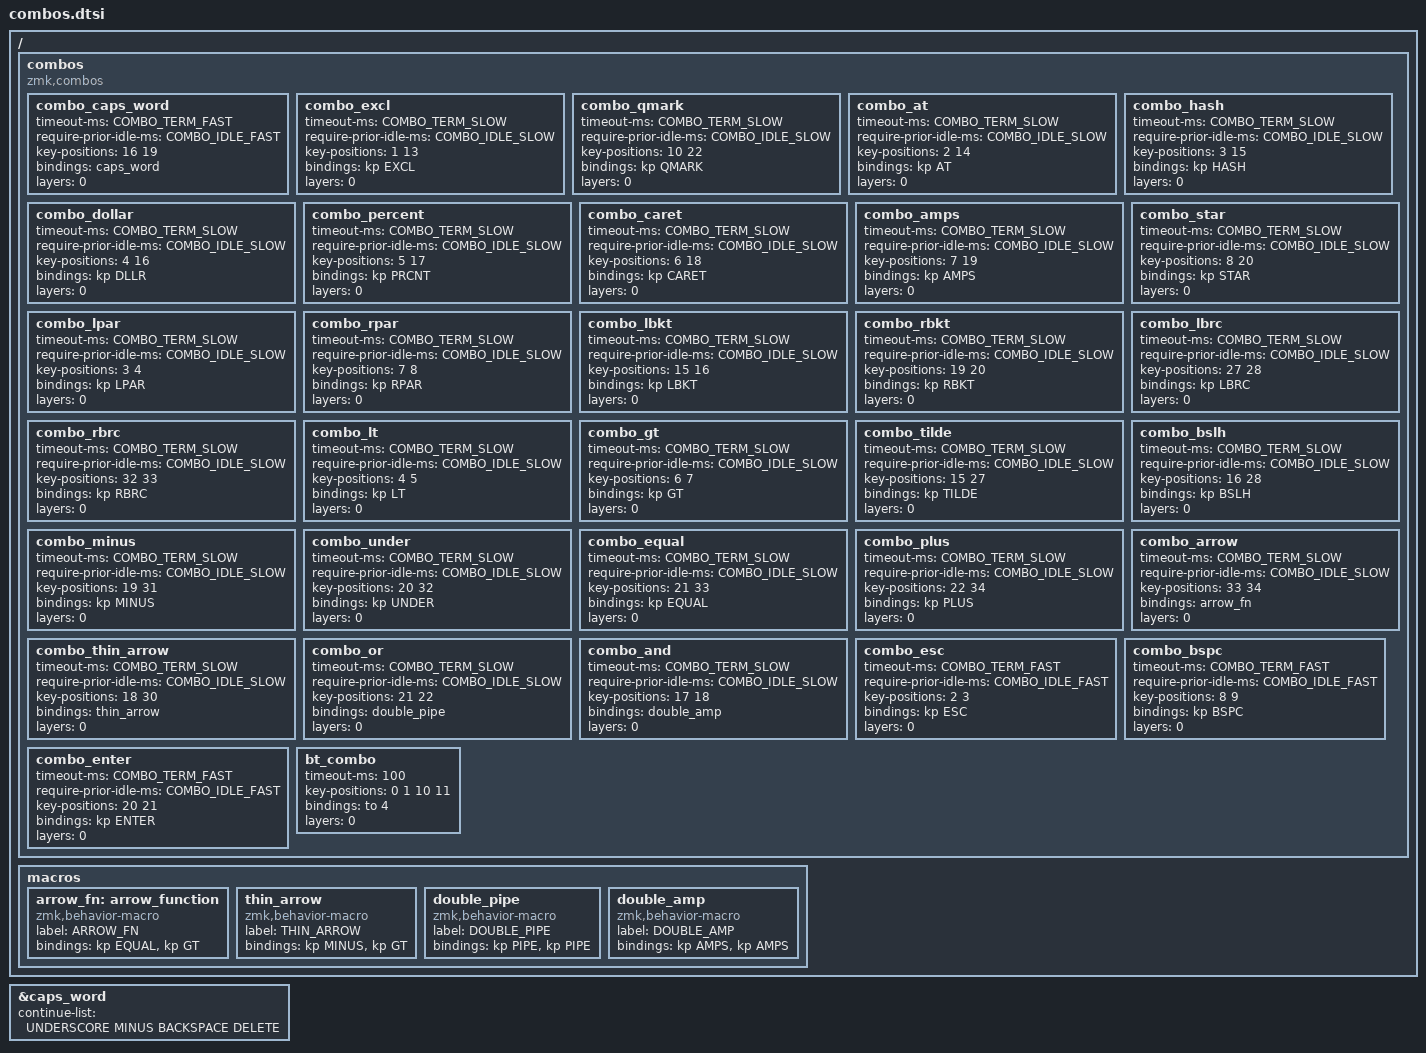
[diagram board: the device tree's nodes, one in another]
/*
 * Combos for 6-column Corne (42 keys)
 * Uses zmk-helpers/key-labels/42.h for position labels
 * Optimized for iOS/Swift, JavaScript/TypeScript, and Java
 *
 * COMBO QUICK REFERENCE:
 * Symbols (vertical):  Q+A=!  W+S=@  E+D=#  R+F=$  T+G=%  Y+H=^  U+J=&  I+K=*  ;+P=?
 * Brackets (horiz):    E+R=(  U+I=)  D+F=[  J+K=]  C+V={  ,+.=}  R+T=<  Y+U=>
 * Operators (diag):    D+C=~  F+V=\  J+M=-  K+,=_  L+.==  P+/=+
 * Programming:         .+/==>  H+N=->  G+H=&&  L+P=||
 * Comfort:             W+E=ESC  I+O=BSPC  K+L=ENTER  F+J=CapsWord
 *
 * Key positions:
 * ╭─────────────────────────────╮ ╭─────────────────────────────╮
 * │  0  1  2  3  4  5           │ │  6  7  8  9 10 11           │
 * │ 12 13 14 15 16 17           │ │ 18 19 20 21 22 23           │
 * │ 24 25 26 27 28 29           │ │ 30 31 32 33 34 35           │
 * ╰──────────╮ 36 37 38         │ │ 39 40 41 ╭──────────────────╯
 *            ╰──────────────────╯ ╰──────────╯
 *
 * Layout reference:
 * ╭─────────────────────────────╮ ╭─────────────────────────────╮
 * │  `  Q  W  E  R  T           │ │  Y  U  I  O  ;  CAPS        │
 * │ ESC A  S  D  F  G           │ │  H  J  K  L  P  '           │
 * │SHFT Z  X  C  V  B           │ │  N  M  ,  .  /  ENT         │
 * ╰──────────╮TAB LWR SPC       │ │ BSP RSE MAG╭─────────────────╯
 *            ╰──────────────────╯ ╰────────────╯
 */

// Combo timing
#define COMBO_TERM_FAST 18
#define COMBO_TERM_SLOW 30
#define COMBO_IDLE_FAST 150
#define COMBO_IDLE_SLOW 50

/ {
    combos {
        compatible = "zmk,combos";

        // ========== CAPS WORD (F+J) ==========
        combo_caps_word {
            timeout-ms = <COMBO_TERM_FAST>;
            require-prior-idle-ms = <COMBO_IDLE_FAST>;
            key-positions = <16 19>;  // F + J
            bindings = <&caps_word>;
            layers = <0>;
        };

        // ========== TIER 1: SYMBOLS (Vertical - top + home row) ==========

        combo_excl {
            timeout-ms = <COMBO_TERM_SLOW>;
            require-prior-idle-ms = <COMBO_IDLE_SLOW>;
            key-positions = <1 13>;  // Q + A
            bindings = <&kp EXCL>;   // !
            layers = <0>;
        };

        combo_qmark {
            timeout-ms = <COMBO_TERM_SLOW>;
            require-prior-idle-ms = <COMBO_IDLE_SLOW>;
            key-positions = <10 22>; // ; + P
            bindings = <&kp QMARK>;  // ?
            layers = <0>;
        };

        combo_at {
            timeout-ms = <COMBO_TERM_SLOW>;
            require-prior-idle-ms = <COMBO_IDLE_SLOW>;
            key-positions = <2 14>;  // W + S
            bindings = <&kp AT>;     // @
            layers = <0>;
        };

        combo_hash {
            timeout-ms = <COMBO_TERM_SLOW>;
            require-prior-idle-ms = <COMBO_IDLE_SLOW>;
            key-positions = <3 15>;  // E + D
            bindings = <&kp HASH>;   // #
            layers = <0>;
        };

        combo_dollar {
            timeout-ms = <COMBO_TERM_SLOW>;
            require-prior-idle-ms = <COMBO_IDLE_SLOW>;
            key-positions = <4 16>;  // R + F
            bindings = <&kp DLLR>;   // $
            layers = <0>;
        };

        combo_percent {
            timeout-ms = <COMBO_TERM_SLOW>;
            require-prior-idle-ms = <COMBO_IDLE_SLOW>;
            key-positions = <5 17>;  // T + G
            bindings = <&kp PRCNT>;  // %
            layers = <0>;
        };

        combo_caret {
            timeout-ms = <COMBO_TERM_SLOW>;
            require-prior-idle-ms = <COMBO_IDLE_SLOW>;
            key-positions = <6 18>;  // Y + H
            bindings = <&kp CARET>;  // ^
            layers = <0>;
        };

        combo_amps {
            timeout-ms = <COMBO_TERM_SLOW>;
            require-prior-idle-ms = <COMBO_IDLE_SLOW>;
            key-positions = <7 19>;  // U + J
            bindings = <&kp AMPS>;   // &
            layers = <0>;
        };

        combo_star {
            timeout-ms = <COMBO_TERM_SLOW>;
            require-prior-idle-ms = <COMBO_IDLE_SLOW>;
            key-positions = <8 20>;  // I + K
            bindings = <&kp STAR>;   // *
            layers = <0>;
        };

        // ========== TIER 2: BRACKETS (Horizontal - adjacent keys) ==========

        combo_lpar {
            timeout-ms = <COMBO_TERM_SLOW>;
            require-prior-idle-ms = <COMBO_IDLE_SLOW>;
            key-positions = <3 4>;   // E + R
            bindings = <&kp LPAR>;   // (
            layers = <0>;
        };

        combo_rpar {
            timeout-ms = <COMBO_TERM_SLOW>;
            require-prior-idle-ms = <COMBO_IDLE_SLOW>;
            key-positions = <7 8>;   // U + I
            bindings = <&kp RPAR>;   // )
            layers = <0>;
        };

        combo_lbkt {
            timeout-ms = <COMBO_TERM_SLOW>;
            require-prior-idle-ms = <COMBO_IDLE_SLOW>;
            key-positions = <15 16>; // D + F
            bindings = <&kp LBKT>;   // [
            layers = <0>;
        };

        combo_rbkt {
            timeout-ms = <COMBO_TERM_SLOW>;
            require-prior-idle-ms = <COMBO_IDLE_SLOW>;
            key-positions = <19 20>; // J + K
            bindings = <&kp RBKT>;   // ]
            layers = <0>;
        };

        combo_lbrc {
            timeout-ms = <COMBO_TERM_SLOW>;
            require-prior-idle-ms = <COMBO_IDLE_SLOW>;
            key-positions = <27 28>; // C + V
            bindings = <&kp LBRC>;   // {
            layers = <0>;
        };

        combo_rbrc {
            timeout-ms = <COMBO_TERM_SLOW>;
            require-prior-idle-ms = <COMBO_IDLE_SLOW>;
            key-positions = <32 33>; // , + .
            bindings = <&kp RBRC>;   // }
            layers = <0>;
        };

        combo_lt {
            timeout-ms = <COMBO_TERM_SLOW>;
            require-prior-idle-ms = <COMBO_IDLE_SLOW>;
            key-positions = <4 5>;   // R + T
            bindings = <&kp LT>;     // <
            layers = <0>;
        };

        combo_gt {
            timeout-ms = <COMBO_TERM_SLOW>;
            require-prior-idle-ms = <COMBO_IDLE_SLOW>;
            key-positions = <6 7>;   // Y + U
            bindings = <&kp GT>;     // >
            layers = <0>;
        };

        // ========== TIER 3: OPERATORS (Home + bottom row) ==========

        combo_tilde {
            timeout-ms = <COMBO_TERM_SLOW>;
            require-prior-idle-ms = <COMBO_IDLE_SLOW>;
            key-positions = <15 27>; // D + C
            bindings = <&kp TILDE>;  // ~
            layers = <0>;
        };

        combo_bslh {
            timeout-ms = <COMBO_TERM_SLOW>;
            require-prior-idle-ms = <COMBO_IDLE_SLOW>;
            key-positions = <16 28>; // F + V
            bindings = <&kp BSLH>;   // backslash
            layers = <0>;
        };

        combo_minus {
            timeout-ms = <COMBO_TERM_SLOW>;
            require-prior-idle-ms = <COMBO_IDLE_SLOW>;
            key-positions = <19 31>; // J + M
            bindings = <&kp MINUS>;  // -
            layers = <0>;
        };

        combo_under {
            timeout-ms = <COMBO_TERM_SLOW>;
            require-prior-idle-ms = <COMBO_IDLE_SLOW>;
            key-positions = <20 32>; // K + ,
            bindings = <&kp UNDER>;  // _
            layers = <0>;
        };

        combo_equal {
            timeout-ms = <COMBO_TERM_SLOW>;
            require-prior-idle-ms = <COMBO_IDLE_SLOW>;
            key-positions = <21 33>; // L + .
            bindings = <&kp EQUAL>;  // =
            layers = <0>;
        };

        combo_plus {
            timeout-ms = <COMBO_TERM_SLOW>;
            require-prior-idle-ms = <COMBO_IDLE_SLOW>;
            key-positions = <22 34>; // P + /
            bindings = <&kp PLUS>;   // +
            layers = <0>;
        };

        // ========== SPECIAL: Programming Operators ==========

        combo_arrow {
            timeout-ms = <COMBO_TERM_SLOW>;
            require-prior-idle-ms = <COMBO_IDLE_SLOW>;
            key-positions = <33 34>; // . + /
            bindings = <&arrow_fn>;  // =>
            layers = <0>;
        };

        combo_thin_arrow {
            timeout-ms = <COMBO_TERM_SLOW>;
            require-prior-idle-ms = <COMBO_IDLE_SLOW>;
            key-positions = <18 30>; // H + N (vertical, arrow-like)
            bindings = <&thin_arrow>; // ->
            layers = <0>;
        };

        combo_or {
            timeout-ms = <COMBO_TERM_SLOW>;
            require-prior-idle-ms = <COMBO_IDLE_SLOW>;
            key-positions = <21 22>; // L + P (horizontal adjacent)
            bindings = <&double_pipe>; // ||
            layers = <0>;
        };

        combo_and {
            timeout-ms = <COMBO_TERM_SLOW>;
            require-prior-idle-ms = <COMBO_IDLE_SLOW>;
            key-positions = <17 18>; // G + H (horizontal center)
            bindings = <&double_amp>; // &&
            layers = <0>;
        };

        // ========== COMFORT COMBOS (Phase 2) ==========

        combo_esc {
            timeout-ms = <COMBO_TERM_FAST>;
            require-prior-idle-ms = <COMBO_IDLE_FAST>;
            key-positions = <2 3>;   // W + E
            bindings = <&kp ESC>;
            layers = <0>;
        };

        combo_bspc {
            timeout-ms = <COMBO_TERM_FAST>;
            require-prior-idle-ms = <COMBO_IDLE_FAST>;
            key-positions = <8 9>;   // I + O
            bindings = <&kp BSPC>;
            layers = <0>;
        };

        combo_enter {
            timeout-ms = <COMBO_TERM_FAST>;
            require-prior-idle-ms = <COMBO_IDLE_FAST>;
            key-positions = <20 21>; // K + L
            bindings = <&kp ENTER>;
            layers = <0>;
        };

        // ========== BT LAYER ACCESS (4 corners) ==========

        bt_combo {
            timeout-ms = <100>;
            key-positions = <0 1 10 11>;  // ` Q ; CAPS (four corners)
            bindings = <&to 4>;
            layers = <0>;
        };
    };

    macros {
        // Arrow function macro: =>
        arrow_fn: arrow_function {
            compatible = "zmk,behavior-macro";
            label = "ARROW_FN";
            #binding-cells = <0>;
            bindings = <&kp EQUAL &kp GT>;
        };

        // Thin arrow macro: -> (Swift function types)
        thin_arrow: thin_arrow {
            compatible = "zmk,behavior-macro";
            label = "THIN_ARROW";
            #binding-cells = <0>;
            bindings = <&kp MINUS &kp GT>;
        };

        // Logical OR macro: ||
        double_pipe: double_pipe {
            compatible = "zmk,behavior-macro";
            label = "DOUBLE_PIPE";
            #binding-cells = <0>;
            bindings = <&kp PIPE &kp PIPE>;
        };

        // Logical AND macro: &&
        double_amp: double_amp {
            compatible = "zmk,behavior-macro";
            label = "DOUBLE_AMP";
            #binding-cells = <0>;
            bindings = <&kp AMPS &kp AMPS>;
        };
    };
};

// Configure Caps Word to continue on underscore, minus, backspace, delete
&caps_word {
    continue-list = <UNDERSCORE MINUS BACKSPACE DELETE>;
};
